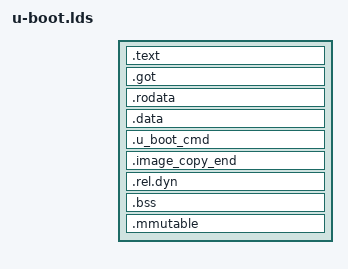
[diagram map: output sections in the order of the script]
/*
 * (C) Copyright 2013
 * David Feng <fenghua@phytium.com.cn>
 *
 * (C) Copyright 2002
 * Gary Jennejohn, DENX Software Engineering, <garyj@denx.de>
 *
 * SPDX-License-Identifier:	GPL-2.0+
 */

OUTPUT_FORMAT("elf64-littleaarch64", "elf64-littleaarch64", "elf64-littleaarch64")
OUTPUT_ARCH(aarch64)
ENTRY(_start)
SECTIONS
{
	. = 0x00000000;

	. = ALIGN(8);
	.text :
	{
		*(.__image_copy_start)
		CPUDIR/start.o (.text*)
		*(.text*)
	}

	. = ALIGN(8);
	.got : {
		__got_start = .;
		*(.got)
		. = ALIGN(8);
		__got_end__ = .;
	}
	. = ALIGN(8);
	.rodata : { *(SORT_BY_ALIGNMENT(SORT_BY_NAME(.rodata*))) }

	. = ALIGN(8);
	.data : {
		*(.data*)
	}

	. = ALIGN(8);

	. = .;
	__u_boot_cmd_start = .;
	.u_boot_cmd : { *(.u_boot_cmd) }
	__u_boot_cmd_end = .;

	. = ALIGN(8);

	.image_copy_end :
	{
		*(.__image_copy_end)
	}

	. = ALIGN(8);

	.rel.dyn : {
		__rel_dyn_start = .;
		*(.rel*)
		__rel_dyn_end = .;
	}


	_end = .;

	.bss __rel_dyn_start (OVERLAY) : {
		__bss_start = .;
		*(.bss)
		 . = ALIGN(8);
		__bss_end = .;
	}

	/*
	 * Deprecated: this MMU section is used by pxa at present but
	 * should not be used by new boards/CPUs.
	 */
	. = ALIGN(4096);
	.mmutable : {
		*(.mmutable)
	}

	/DISCARD/ : { *(.dynsym) }
	/DISCARD/ : { *(.dynstr*) }
	/DISCARD/ : { *(.dynamic*) }
	/DISCARD/ : { *(.plt*) }
	/DISCARD/ : { *(.interp*) }
	/DISCARD/ : { *(.gnu*) }
}
